# ESP32S31_RADIO register map
Vendor: Espressif; Series: ESP32-S31; File version: 3.52
Registers are 32-bit, read-write, no defined reset value unless marked. A register's access mark holds for its fields unless they carry their own. Offsets are from the block's base; [hi:lo] are bit positions; {n}, {i} and the like mark numbered series; 'fields as' and 'values as' point back to an identical list.

## PHY_NRX_RECOVERED_GAPS — Sparse NRX words absent from the public platform PAC.
Base 0x20107800
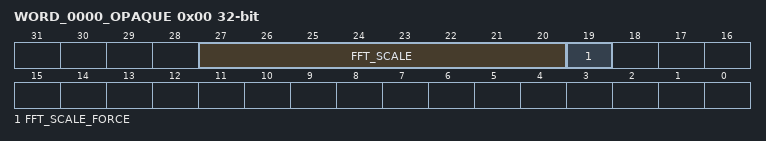
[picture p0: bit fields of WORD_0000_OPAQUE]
0x00 WORD_0000_OPAQUE — Opaque: meaning not established. Complete phy_fft_scale_force read-modify-writes this word.
  [27:20] FFT_SCALE — Project-assigned name. FFT scale complete phy_fft_scale_force publishes from its second argument.
  [19] FFT_SCALE_FORCE — Project-assigned name. Force the FFT scale to FFT_SCALE; complete phy_fft_scale_force publishes its first argument here.
0x0C WORD_000C_OPAQUE — Opaque: meaning not established. Complete phy_dig_reg_backup saves and restores this word; all field semantics remain unknown.
0x30 WORD_0030_OPAQUE — Opaque: meaning not established. Complete phy_spur_reg_write_one_tone reads and replaces this word on three control-flow paths; individual hardware fields remain unnamed.
0x98 WORD_0098_OPAQUE — Opaque: meaning not established. Complete phy_freq_correct read-modify-writes this word; individual fields remain unnamed.
0xB8 WORD_00B8_OPAQUE — Opaque: meaning not established. Complete phy_bb_cfo_cfg replaces bits 31:29 with the observed constant pattern while preserving bits 28:0; the hardware field meaning remains unknown.
  [31:29] BITS_29_31_OPAQUE — Opaque: meaning not established.
0x104 WORD_0104_OPAQUE — Opaque: meaning not established. Complete phy_chan_filt_set read-modify-writes this word and complete phy_dig_reg_backup saves/restores it.

## PHY_BB_RECOVERED_GAPS — Sparse BB words absent from the public platform PAC.
Base 0x20107C00
0x14 WORD_0014_OPAQUE — Opaque: meaning not established. Complete phy_spur_coef_cfg clears bit 13 through two read-modify-write paths; all hardware field names remain unknown.
  [13] BIT_13_OPAQUE — Opaque: meaning not established.
0x58 WORD_0058_OPAQUE — Opaque: meaning not established. Complete phy_set_cca_cnt read-modify-writes this word; individual fields remain unnamed.
0x5C WORD_005C_OPAQUE access not given — Opaque: meaning not established. Complete phy_get_cca_cnt reads this word; hardware access semantics remain unknown.
0x60 WORD_0060_OPAQUE access not given — Opaque: meaning not established. Complete phy_get_cca_cnt reads this word; hardware access semantics remain unknown.
0xE8 WORD_00E8_OPAQUE — Opaque: meaning not established. Complete phy_bb_cfo_cfg reads and replaces this word; individual hardware fields remain unnamed.
0xEC WORD_00EC_OPAQUE — Opaque: meaning not established. Complete phy_bb_cfo_cfg replaces this word and independently read-modify-writes bit 12; the hardware field meaning remains unknown.
  [12] BIT_12_OPAQUE — Opaque: meaning not established.

## PHY_BRX_RECOVERED_GAPS — Sparse BRX words absent from the public platform PAC.
Base 0x20108000
0x50 WORD_0050_OPAQUE — Opaque: meaning not established. Complete phy_freq_correct read-modify-writes this word; individual fields remain unnamed.

## IEEE802154_INTERRUPT_ROUTE — The two CPU interrupt-matrix words for ESP32-S31 modem source 132 (MODEM_ZB_MAC). This source-specific view is retained with the IEEE 802.15.4 owner and publishes only the generated field readers needed to prove that a polled or validation transaction starts with both CPU routes detached.
Base 0x20585210
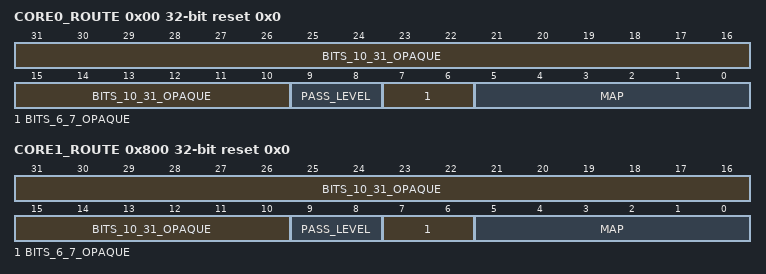
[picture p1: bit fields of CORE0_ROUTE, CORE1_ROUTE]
0x00 CORE0_ROUTE reset 0x0 — Project-assigned name. Core-zero destination and privilege routing for MODEM_ZB_MAC.
  [31:10] BITS_10_31_OPAQUE — Opaque: meaning not established. Bits the vendor declares reserved, retained solely so reset-state observation cannot erase an unexpected nonzero value.
  [9:8] PASS_LEVEL — Project-assigned name. Privilege pass/remap level selected for the peripheral source.
  [7:6] BITS_6_7_OPAQUE — Opaque: meaning not established. Bits the vendor declares reserved, retained solely so reset-state observation cannot erase an unexpected nonzero value.
  [5:0] MAP — Project-assigned name. CPU-interrupt destination selected for the peripheral source.
0x800 CORE1_ROUTE reset 0x0 — Project-assigned name. Core-one destination and privilege routing for MODEM_ZB_MAC.
  fields as CORE0_ROUTE

## MODEM_ETM — ESP32-S31 modem event-task matrix at MODEM_BASE + 0x8800, shared by the IEEE 802.15.4 and Bluetooth lifecycles. The public IEEE 802.15.4 driver names the channel-enable, set and clear words and the per-channel event/task pair at an eight-byte stride, and programs channels zero and one; the BTDM runtime programs channels four through seven through the same words. Channel bits and identifiers without a reviewed user remain absent and no reset values are claimed.
Base 0x20108800
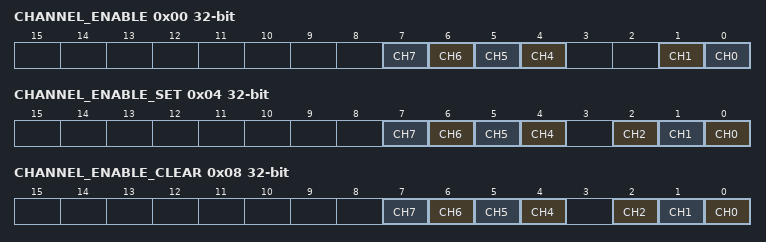
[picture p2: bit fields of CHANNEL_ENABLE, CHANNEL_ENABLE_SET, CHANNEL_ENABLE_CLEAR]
0x00 CHANNEL_ENABLE ro — Project-assigned name. Channel-enable status word. The IEEE 802.15.4 driver reads it to decide whether a channel must be disabled; the BTDM runtime reads the complete word.
  [n] CH{n} (n=4..7) — Channel {n} is enabled.
  [1] CH1 — Channel 1 is enabled.
  [0] CH0 — Channel 0 is enabled.
0x04 CHANNEL_ENABLE_SET wo — Project-assigned name. Channel-enable set word. Its fields are write-trigger: writing 1 enables that channel and writing 0 has no effect, as in the ESP32-S31 SoC ETM of identical layout. This semantics is not yet verified on the modem ETM hardware. The IEEE 802.15.4 driver writes the word back after reading it with the selected channel bit added; the BTDM runtime writes complete channel images.
  [n] CH{n} (n=4..7) — Writing 1 enables channel {n}.
  [2] CH2 — Writing 1 enables channel 2.
  [1] CH1 — Writing 1 enables channel 1.
  [0] CH0 — Writing 1 enables channel 0.
0x08 CHANNEL_ENABLE_CLEAR wo — Project-assigned name. Channel-enable clear word. Its fields are write-trigger: writing 1 disables that channel and writing 0 has no effect, as in the ESP32-S31 SoC ETM of identical layout. This semantics is not yet verified on the modem ETM hardware. The IEEE 802.15.4 driver writes the word back after reading it with the selected channel bit added; the BTDM runtime writes complete single-channel images.
  [n] CH{n} (n=4..7) — Writing 1 disables channel {n}.
  [2] CH2 — Project-assigned name. Writing 1 disables channel 2.
  [1] CH1 — Writing 1 disables channel 1.
  [0] CH0 — Writing 1 disables channel 0.
{0xC+8i} CH{i}_EVENT (i=0..7) — Project-assigned name. Complete event identifier monitored by the selected channel.
  [31:0] ID — Event identifier written as a complete word.
    79=IEEE802154_TIMER1_OVERFLOW; 80=IEEE802154_TIMER0_OVERFLOW
{0x10+8i} CH{i}_TASK (i=0..7) — Project-assigned name. Complete task identifier triggered when the selected channel's event occurs.
  [31:0] ID — Task identifier written as a complete word.
    84=IEEE802154_ED_TRIG_TX; 85=IEEE802154_RX_START; 88=IEEE802154_TX_START

## WIFI_MAC_INTERFACE_ADDRESS — Four interface-address pairs consumed by MAC receive filtering.
Base 0x2010405C
{0x0+8i} ADDRESS_LOW{i} (i=0..3) — Project-assigned name. Interface MAC bytes 0..3 in little-endian order, published by the first full-word store.
  [31:0] BYTES_0_3 — Project-assigned name.
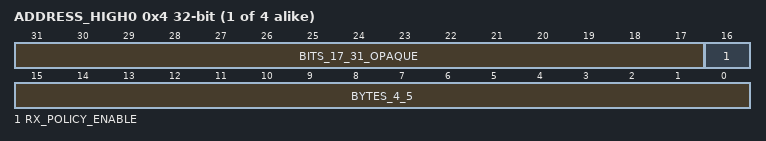
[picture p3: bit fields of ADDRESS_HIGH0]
{0x4+8i} ADDRESS_HIGH{i} (i=0..3) — Project-assigned name. Interface MAC bytes 4..5 are published as a full-word store before a separate fresh-read RMW sets receive-policy enable bit 16.
  [31:17] BITS_17_31_OPAQUE — Opaque: meaning not established.
  [16] RX_POLICY_ENABLE — Project-assigned name. Set by a separate fresh-read RMW in hal_mac_set_addr and by the reachable associated-STA policy branch.
  [15:0] BYTES_4_5 — Project-assigned name.
